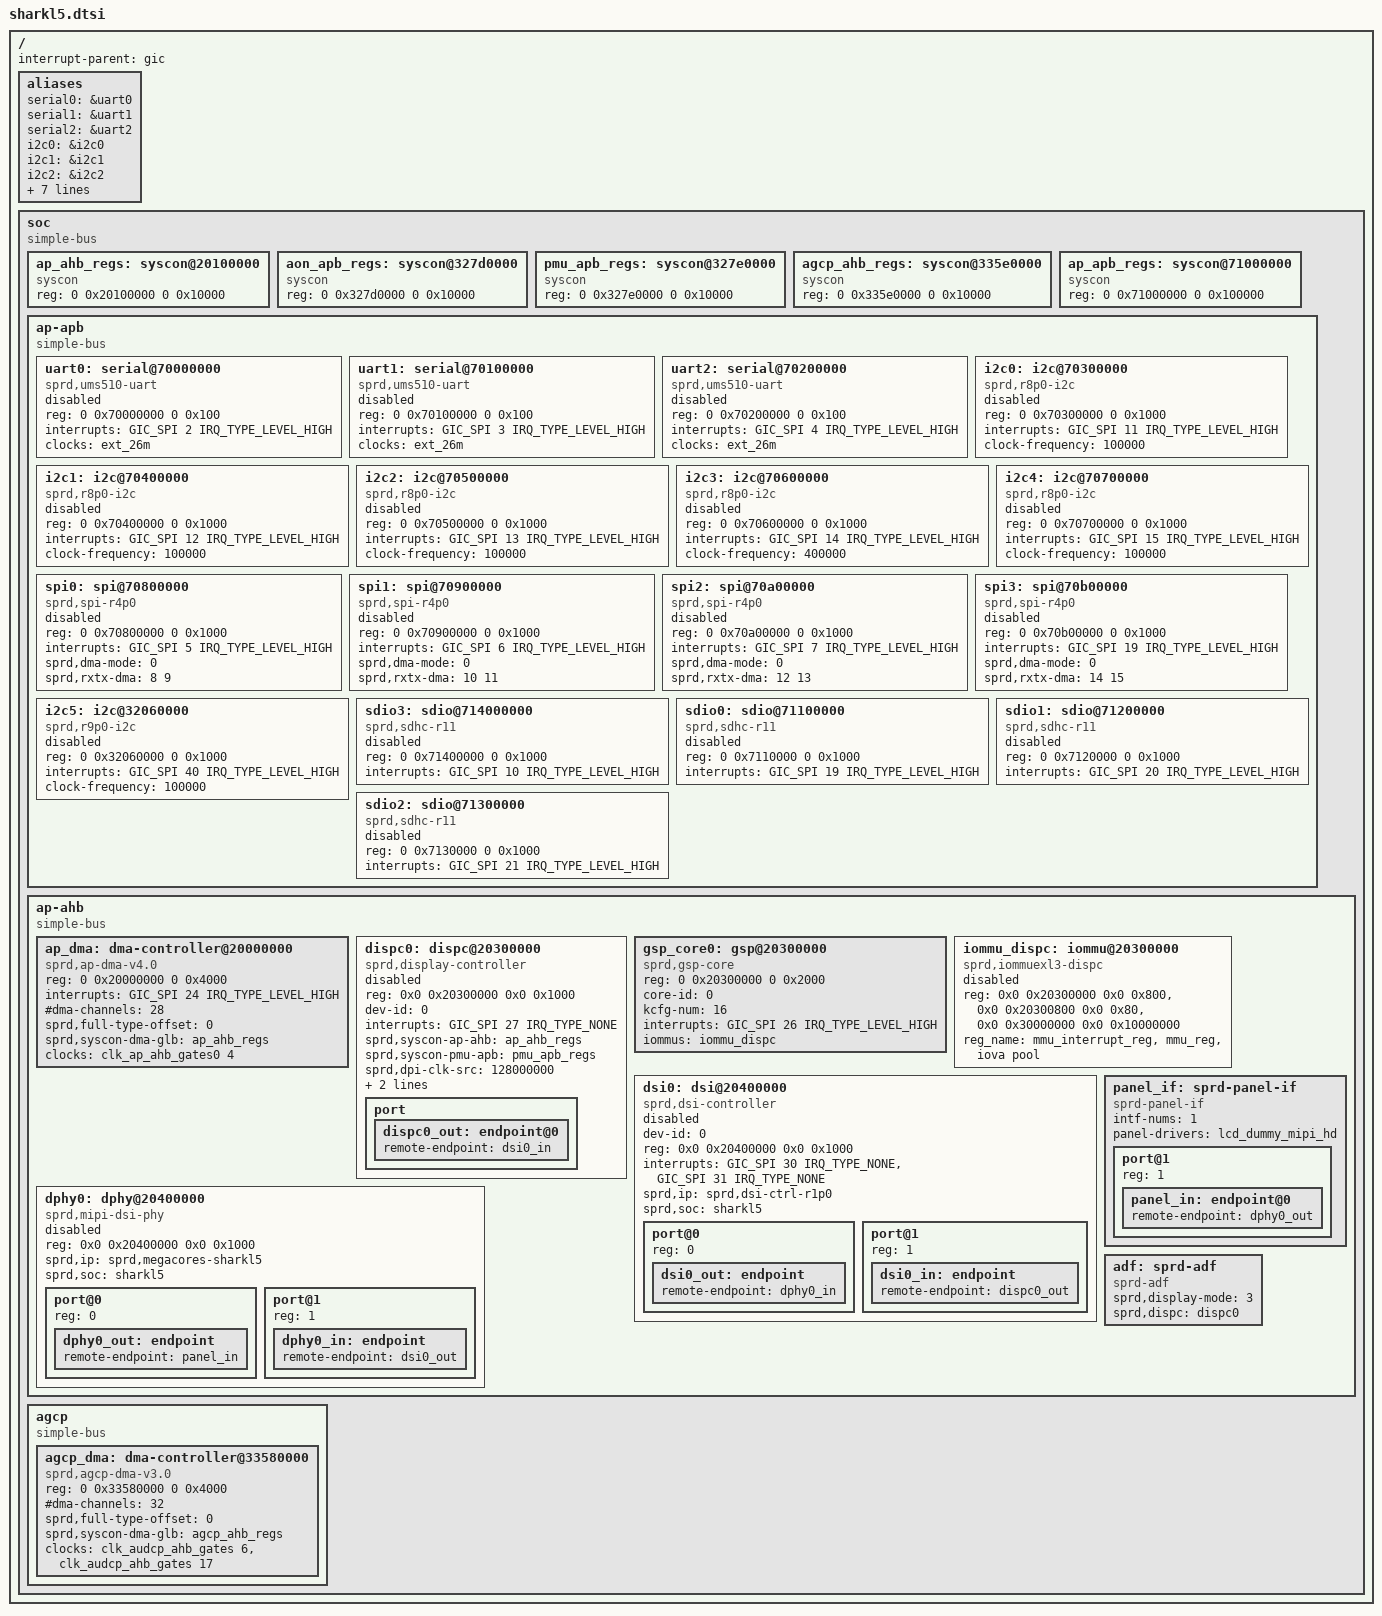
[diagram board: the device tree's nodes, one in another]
// SPDX-License-Identifier: (GPL-2.0+ OR MIT)
/*
 * Spreadtrum Sharkl5 platform DTS file
 *
 * Copyright (C) 2018, Spreadtrum Communications Inc.
 */

#include <dt-bindings/interrupt-controller/arm-gic.h>
#include "lcd/lcd_dummy_mipi.dtsi"

/ {
	interrupt-parent = <&gic>;
	#address-cells = <2>;
	#size-cells = <2>;

	aliases {
		serial0 = &uart0;
		serial1 = &uart1;
		serial2 = &uart2;
		i2c0 = &i2c0;
		i2c1 = &i2c1;
		i2c2 = &i2c2;
		i2c3 = &i2c3;
		i2c4 = &i2c4;
		i2c5 = &i2c5;
		spi0 = &spi0;
		spi1 = &spi1;
		spi2 = &spi2;
		spi3 = &spi3;
	};

	soc: soc {
		compatible = "simple-bus";
		#address-cells = <2>;
		#size-cells = <2>;
		ranges;

		ap_ahb_regs: syscon@20100000 {
			compatible = "syscon";
			reg = <0 0x20100000 0 0x10000>;
		};

		aon_apb_regs: syscon@327d0000 {
			compatible = "syscon";
			reg = <0 0x327d0000 0 0x10000>;
		};

		pmu_apb_regs: syscon@327e0000 {
			compatible = "syscon";
			reg = <0 0x327e0000 0 0x10000>;
		};

		agcp_ahb_regs: syscon@335e0000 {
			compatible = "syscon";
			reg = <0 0x335e0000 0 0x10000>;
		};

		ap_apb_regs: syscon@71000000 {
			compatible = "syscon";
			reg = <0 0x71000000 0 0x100000>;
		};

		ap-apb {
			compatible = "simple-bus";
			#address-cells = <2>;
			#size-cells = <2>;
			ranges;

			uart0: serial@70000000 {
				compatible = "sprd,ums510-uart",
					     "sprd,sc9836-uart";
				reg = <0 0x70000000 0 0x100>;
				interrupts = <GIC_SPI 2 IRQ_TYPE_LEVEL_HIGH>;
				clock-names = "uart", "source", "enable";
				clocks = <&ext_26m>;
				status = "disabled";
			};

			uart1: serial@70100000 {
				compatible = "sprd,ums510-uart",
					     "sprd,sc9836-uart";
				reg = <0 0x70100000 0 0x100>;
				interrupts = <GIC_SPI 3 IRQ_TYPE_LEVEL_HIGH>;
				clock-names = "uart", "source", "enable";
				clocks = <&ext_26m>;
				status = "disabled";
			};

			uart2: serial@70200000 {
				compatible = "sprd,ums510-uart",
					     "sprd,sc9836-uart";
				reg = <0 0x70200000 0 0x100>;
				interrupts = <GIC_SPI 4 IRQ_TYPE_LEVEL_HIGH>;
				clock-names = "uart", "source", "enable";
				clocks = <&ext_26m>;
				status = "disabled";
			};

			i2c0: i2c@70300000 {
				compatible = "sprd,r8p0-i2c";
				reg = <0 0x70300000 0 0x1000>;
				interrupts = <GIC_SPI 11 IRQ_TYPE_LEVEL_HIGH>;
				clock-names = "i2c","source", "enable";
				clock-frequency = <100000>;
				#address-cells = <1>;
				#size-cells = <0>;
				status = "disabled";
			};

			i2c1: i2c@70400000 {
				compatible = "sprd,r8p0-i2c";
				reg = <0 0x70400000 0 0x1000>;
				interrupts = <GIC_SPI 12 IRQ_TYPE_LEVEL_HIGH>;
				clock-names = "i2c","source", "enable";
				clock-frequency = <100000>;
				#address-cells = <1>;
				#size-cells = <0>;
				status = "disabled";
			};

			i2c2: i2c@70500000 {
				compatible = "sprd,r8p0-i2c";
				reg = <0 0x70500000 0 0x1000>;
				interrupts = <GIC_SPI 13 IRQ_TYPE_LEVEL_HIGH>;
				clock-names = "i2c","source", "enable";
				clock-frequency = <100000>;
				#address-cells = <1>;
				#size-cells = <0>;
				status = "disabled";
			};

			i2c3: i2c@70600000 {
				compatible = "sprd,r8p0-i2c";
				reg = <0 0x70600000 0 0x1000>;
				interrupts = <GIC_SPI 14 IRQ_TYPE_LEVEL_HIGH>;
				clock-names = "i2c","source", "enable";
				clock-frequency = <400000>;
				#address-cells = <1>;
				#size-cells = <0>;
				status = "disabled";
			};

			i2c4: i2c@70700000 {
				compatible = "sprd,r8p0-i2c";
				reg = <0 0x70700000 0 0x1000>;
				interrupts = <GIC_SPI 15 IRQ_TYPE_LEVEL_HIGH>;
				clock-names = "i2c","source", "enable";
				clock-frequency = <100000>;
				#address-cells = <1>;
				#size-cells = <0>;
				status = "disabled";
			};

			spi0: spi@70800000{
				compatible = "sprd,spi-r4p0";
				reg = <0 0x70800000 0 0x1000>;
				interrupts = <GIC_SPI 5 IRQ_TYPE_LEVEL_HIGH>;
				clock-names = "spi", "source", "enable";
				sprd,dma-mode = <0>;
				sprd,rxtx-dma = <8 9>;
				dma-names = "rx_chn", "tx_chn";
				#address-cells = <1>;
				#size-cells = <0>;
				status = "disabled";
			};

			spi1: spi@70900000{
				compatible = "sprd,spi-r4p0";
				reg = <0 0x70900000 0 0x1000>;
				interrupts = <GIC_SPI 6 IRQ_TYPE_LEVEL_HIGH>;
				clock-names = "spi", "source", "enable";
				sprd,dma-mode = <0>;
				sprd,rxtx-dma = <10 11>;
				dma-names = "rx_chn", "tx_chn";
				#address-cells = <1>;
				#size-cells = <0>;
				status = "disabled";
			};

			spi2: spi@70a00000{
				compatible = "sprd,spi-r4p0";
				reg = <0 0x70a00000 0 0x1000>;
				interrupts = <GIC_SPI 7 IRQ_TYPE_LEVEL_HIGH>;
				clock-names = "spi", "source", "enable";
				sprd,dma-mode = <0>;
				sprd,rxtx-dma = <12 13>;
				dma-names = "rx_chn", "tx_chn";
				#address-cells = <1>;
				#size-cells = <0>;
				status = "disabled";
			};

			spi3: spi@70b00000{
				compatible = "sprd,spi-r4p0";
				reg = <0 0x70b00000 0 0x1000>;
				interrupts = <GIC_SPI 19 IRQ_TYPE_LEVEL_HIGH>;
				clock-names = "spi", "source", "enable";
				sprd,dma-mode = <0>;
				sprd,rxtx-dma = <14 15>;
				dma-names = "rx_chn", "tx_chn";
				#address-cells = <1>;
				#size-cells = <0>;
				status = "disabled";
			};

			i2c5: i2c@32060000 {
				compatible = "sprd,r9p0-i2c";
				reg = <0 0x32060000 0 0x1000>;
				interrupts = <GIC_SPI 40 IRQ_TYPE_LEVEL_HIGH>;
				clock-names = "i2c","source", "enable",
					"clk_hw_i2c";
				clock-frequency = <100000>;
				#address-cells = <1>;
				#size-cells = <0>;
				status = "disabled";
			};

			sdio3: sdio@714000000 {
				compatible = "sprd,sdhc-r11";
				reg = <0 0x71400000 0 0x1000>;
				interrupts = <GIC_SPI 10 IRQ_TYPE_LEVEL_HIGH>;
				status = "disabled";
			};

			sdio0: sdio@71100000 {
				compatible = "sprd,sdhc-r11";
				reg = <0 0x7110000 0 0x1000>;
				interrupts = <GIC_SPI 19 IRQ_TYPE_LEVEL_HIGH>;
				status = "disabled";
			};

			sdio1: sdio@71200000 {
				compatible = "sprd,sdhc-r11";
				reg = <0 0x7120000 0 0x1000>;
				interrupts = <GIC_SPI 20 IRQ_TYPE_LEVEL_HIGH>;
				status = "disabled";
			};

			sdio2: sdio@71300000 {
				compatible = "sprd,sdhc-r11";
				reg = <0 0x7130000 0 0x1000>;
				interrupts = <GIC_SPI 21 IRQ_TYPE_LEVEL_HIGH>;
				status = "disabled";
			};
		};

		ap-ahb {
			compatible = "simple-bus";
			#address-cells = <2>;
			#size-cells = <2>;
			ranges;

			ap_dma: dma-controller@20000000 {
				compatible = "sprd,ap-dma-v4.0";
				reg = <0 0x20000000 0 0x4000>;
				interrupts = <GIC_SPI 24 IRQ_TYPE_LEVEL_HIGH>;
				#dma-cells = <1>;
				#dma-channels = <28>;
				sprd,full-type-offset = <0>;
				sprd,syscon-dma-glb = <&ap_ahb_regs>;
				clock-names = "enable";
				clocks = <&clk_ap_ahb_gates0 4>;
			};

			dispc0: dispc@20300000 {
				compatible = "sprd,display-controller";
				reg = <0x0 0x20300000 0x0 0x1000>;
				dev-id = <0>;
				interrupts = <GIC_SPI 27 IRQ_TYPE_NONE>;
				sprd,syscon-ap-ahb = <&ap_ahb_regs>;
				sprd,syscon-pmu-apb = <&pmu_apb_regs>;
				sprd,dpi-clk-src = <128000000>;
				/*iommus = <&iommu_dispc>;*/
				status = "disabled";

				sprd,ip = "dpu-lite-r2p0";
				sprd,soc = "sharkl5";
				/* output port */
				port {
					dispc0_out: endpoint@0 {
						remote-endpoint = <&dsi0_in>;
					};
				};
			};

			gsp_core0: gsp@20300000 {
				compatible = "sprd,gsp-core";
				reg = <0 0x20300000  0 0x2000>;
				core-id = <0>;
				kcfg-num = <16>;
				interrupts = <GIC_SPI 26 IRQ_TYPE_LEVEL_HIGH>;
				iommus = <&iommu_dispc>;
			};

			iommu_dispc: iommu@20300000 {
				compatible = "sprd,iommuexl3-dispc";
				reg = <0x0 0x20300000 0x0 0x800>,
				      <0x0 0x20300800 0x0 0x80>,
				      <0x0 0x30000000 0x0 0x10000000>;
				reg_name = "mmu_interrupt_reg","mmu_reg",
					   "iova pool";
				status = "disabled";
				#iommu-cells = <0>;
			};

			dsi0: dsi@20400000{
				compatible = "sprd,dsi-controller";
				#address-cells = <1>;
				#size-cells = <0>;
				dev-id = <0>;
				reg = <0x0 0x20400000 0x0 0x1000>;
				interrupts = <GIC_SPI 30 IRQ_TYPE_NONE>,
					<GIC_SPI 31 IRQ_TYPE_NONE>;
				status = "disabled";

				sprd,ip = "sprd,dsi-ctrl-r1p0";
				sprd,soc = "sharkl5";
				/* output port */
				port@0 {
					reg = <0>;
					dsi0_out: endpoint {
						remote-endpoint = <&dphy0_in>;
					};
				};

				/* input port */
				port@1 {
					reg = <1>;
					dsi0_in: endpoint {
						remote-endpoint = <&dispc0_out>;
					};
				};
			};

			dphy0: dphy@20400000 {
				compatible = "sprd,mipi-dsi-phy";
				#address-cells = <1>;
				#size-cells = <0>;
				reg = <0x0 0x20400000 0x0 0x1000>;
				status = "disabled";

				sprd,ip = "sprd,megacores-sharkl5";
				sprd,soc = "sharkl5";
				/* output port */
				port@0 {
					reg = <0>;
					dphy0_out: endpoint {
						remote-endpoint = <&panel_in>;
					};
				};

				/* input port*/
				port@1 {
					reg = <1>;
					dphy0_in: endpoint {
						remote-endpoint = <&dsi0_out>;
					};
				};
			};

			panel_if: sprd-panel-if {
				compatible = "sprd-panel-if";
				#address-cells = <1>;
				#size-cells = <0>;
				intf-nums = <1>;
				panel-drivers = <
					&lcd_dummy_mipi_hd
				>;
				/* input port */
				port@1 {
				/* WARNING: the reg property must be 1 ! */
					reg = <1>;
					panel_in: endpoint@0 {
						remote-endpoint = <&dphy0_out>;
					};
				};
			};

			adf: sprd-adf {
				compatible = "sprd-adf";
				status = "okay";
				sprd,display-mode = <3>;
				sprd,dispc = <&dispc0>;
			};

		};

		agcp {
			compatible = "simple-bus";
			#address-cells = <2>;
			#size-cells = <2>;
			ranges;

			agcp_dma: dma-controller@33580000 {
				compatible = "sprd,agcp-dma-v3.0";
				reg = <0 0x33580000 0 0x4000>;
				#dma-cells = <1>;
				#dma-channels = <32>;
				sprd,full-type-offset = <0>;
				sprd,syscon-dma-glb = <&agcp_ahb_regs>;
				clock-names = "enable", "ashb_eb";
				clocks = <&clk_audcp_ahb_gates 6>, <&clk_audcp_ahb_gates 17>;
			};
		};
	};
};
